VERSION ""

NS_ :

BS_:

BU_: XXX

BO_ 85 CID_GBIMZC: 8 XXX
 SG_ sig_pclxby : 40|1@1+ (1,0) [0|1] "" XXX
 SG_ sig_extefw : 56|8@1+ (1,0) [0|255] "" XXX

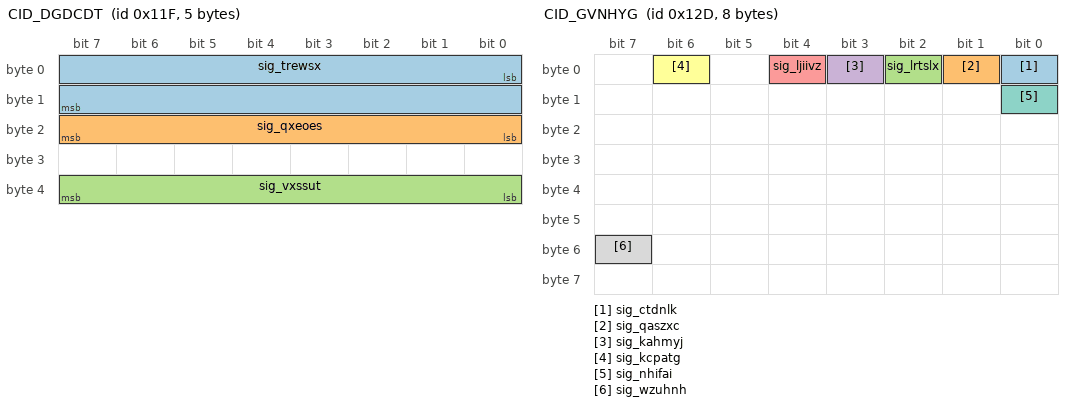
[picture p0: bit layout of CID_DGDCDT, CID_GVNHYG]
BO_ 287 CID_DGDCDT: 5 XXX
 SG_ sig_trewsx : 0|16@1- (0.1,0) [-450|450] "" XXX
 SG_ sig_qxeoes : 16|8@1+ (4,0) [0|1020] "" XXX
 SG_ sig_vxssut : 32|8@1+ (1,0) [0|255] "" XXX

BO_ 289 CID_SAXJDJ: 8 XXX
 SG_ sig_kdftpg : 0|12@1+ (1,0) [0|255] "" XXX

BO_ 301 CID_GVNHYG: 8 XXX
 SG_ sig_ctdnlk : 0|1@0+ (1,0) [0|1] "" XXX
 SG_ sig_qaszxc : 1|1@0+ (1,0) [0|1] "" XXX
 SG_ sig_lrtslx : 2|1@0+ (1,0) [0|1] "" XXX
 SG_ sig_kahmyj : 3|1@0+ (1,0) [0|1] "" XXX
 SG_ sig_ljiivz : 4|1@0+ (1,0) [0|1] "" XXX
 SG_ sig_kcpatg : 6|1@0+ (1,0) [0|1] "" XXX
 SG_ sig_nhifai : 8|1@0+ (1,0) [0|1] "" XXX
 SG_ sig_wzuhnh : 55|1@0+ (1,0) [0|1] "" XXX

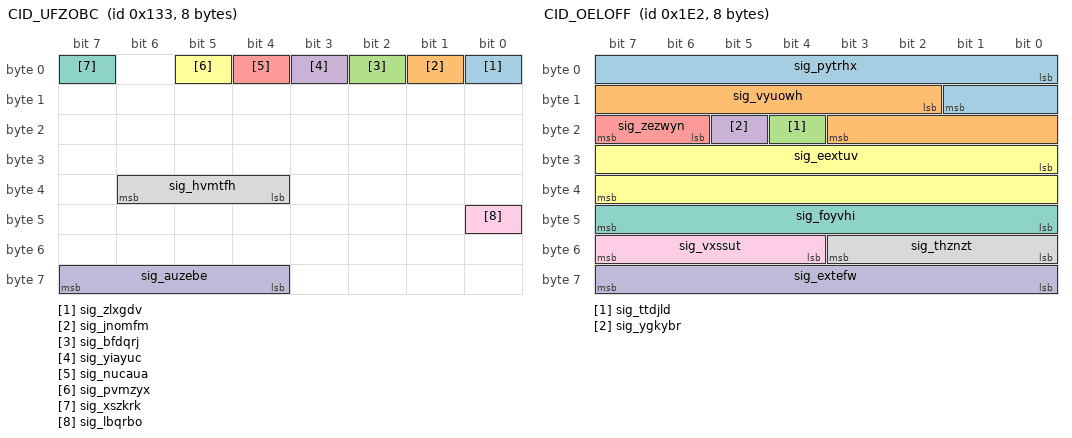
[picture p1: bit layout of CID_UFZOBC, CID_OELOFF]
BO_ 307 CID_UFZOBC: 8 XXX
 SG_ sig_zlxgdv : 0|1@0+ (1,0) [0|1] "" XXX
 SG_ sig_jnomfm : 1|1@1+ (1,0) [0|1] "" XXX
 SG_ sig_bfdqrj : 2|1@1+ (1,0) [0|1] "" XXX
 SG_ sig_yiayuc : 3|1@1+ (1,0) [0|1] "" XXX
 SG_ sig_nucaua : 4|1@0+ (1,0) [0|1] "" XXX
 SG_ sig_pvmzyx : 5|1@0+ (1,0) [0|1] "" XXX
 SG_ sig_xszkrk : 7|1@0+ (1,0) [0|1] "" XXX
 SG_ sig_hvmtfh : 36|3@1+ (1,0) [0|7] "" XXX
 SG_ sig_lbqrbo : 40|1@0+ (1,0) [0|1] "" XXX
 SG_ sig_auzebe : 63|4@0+ (1,0) [0|15] "" XXX

BO_ 482 CID_OELOFF: 8 XXX
 SG_ sig_pytrhx : 0|10@1- (0.01,0) [0|5] "" XXX
 SG_ sig_vyuowh : 10|10@1- (0.01,0) [-5|0] "" XXX
 SG_ sig_ttdjld : 20|1@0+ (1,0) [0|1] "" XXX
 SG_ sig_ygkybr : 21|1@0+ (1,0) [0|1] "" XXX
 SG_ sig_zezwyn : 22|2@1+ (1,0) [0|1] "" XXX
 SG_ sig_eextuv : 24|16@1- (0.1,0) [-780|779.9] "" XXX
 SG_ sig_foyvhi : 47|8@0+ (1,0) [0|255] "" XXX
 SG_ sig_thznzt : 48|4@1+ (1,0) [0|15] "" XXX
 SG_ sig_vxssut : 52|4@1+ (1,0) [0|15] "" XXX
 SG_ sig_extefw : 56|8@1+ (1,0) [0|255] "" XXX

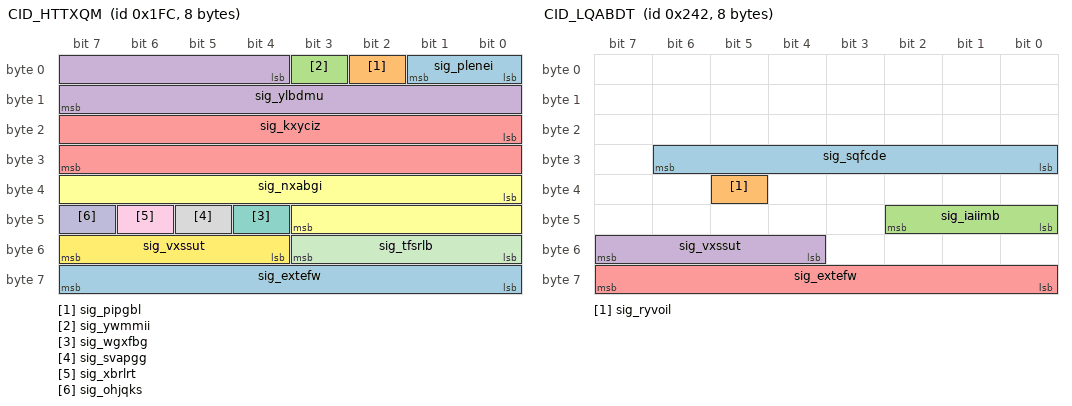
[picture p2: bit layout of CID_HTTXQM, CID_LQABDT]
BO_ 508 CID_HTTXQM: 8 XXX
 SG_ sig_plenei : 0|2@1+ (1,0) [0|1] "" XXX
 SG_ sig_pipgbl : 2|1@1+ (1,0) [0|1] "" XXX
 SG_ sig_ywmmii : 3|1@0+ (1,0) [0|1] "" XXX
 SG_ sig_ylbdmu : 4|12@1- (1,0) [-2048|2047] "" XXX
 SG_ sig_kxyciz : 16|16@1- (0.1,0) [-780|779.9] "Deg" XXX
 SG_ sig_nxabgi : 32|12@1- (1,0) [0|63] "" XXX
 SG_ sig_wgxfbg : 44|1@0+ (1,0) [0|1] "" XXX
 SG_ sig_svapgg : 45|1@1+ (1,0) [0|255] "" XXX
 SG_ sig_xbrlrt : 46|1@1+ (1,0) [0|1] "" XXX
 SG_ sig_ohjqks : 47|1@0+ (1,0) [0|3] "" XXX
 SG_ sig_tfsrlb : 48|4@1+ (1,0) [0|15] "" XXX
 SG_ sig_vxssut : 52|4@1+ (1,0) [0|15] "" XXX
 SG_ sig_extefw : 56|8@1+ (1,0) [0|255] "" XXX

BO_ 578 CID_LQABDT: 8 XXX
 SG_ sig_sqfcde : 30|7@0+ (1,0) [0|127] "" XXX
 SG_ sig_ryvoil : 37|1@0+ (1,0) [0|1] "" XXX
 SG_ sig_iaiimb : 40|3@1+ (1,0) [0|7] "" XXX
 SG_ sig_vxssut : 55|4@0+ (1,0) [0|15] "" XXX
 SG_ sig_extefw : 56|8@1+ (1,0) [0|255] "" XXX

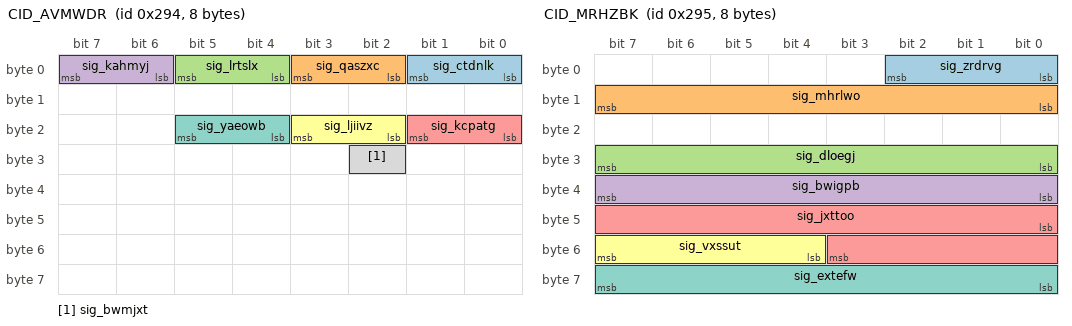
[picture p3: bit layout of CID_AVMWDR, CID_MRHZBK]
BO_ 660 CID_AVMWDR: 8 XXX
 SG_ sig_ctdnlk : 1|2@0+ (1,0) [0|3] "" XXX
 SG_ sig_qaszxc : 3|2@0+ (1,0) [0|3] "" XXX
 SG_ sig_lrtslx : 5|2@0+ (1,0) [0|3] "" XXX
 SG_ sig_kahmyj : 7|2@0+ (1,0) [0|3] "" XXX
 SG_ sig_kcpatg : 17|2@0+ (1,0) [0|3] "" XXX
 SG_ sig_ljiivz : 19|2@0+ (1,0) [0|3] "" XXX
 SG_ sig_yaeowb : 21|2@0+ (1,0) [0|3] "" XXX
 SG_ sig_bwmjxt : 26|1@0+ (1,0) [0|1] "" XXX

BO_ 661 CID_MRHZBK: 8 XXX
 SG_ sig_zrdrvg : 2|3@0+ (1,0) [0|7] "" XXX
 SG_ sig_mhrlwo : 15|8@0+ (1,0) [0|255] "" XXX
 SG_ sig_dloegj : 31|8@0+ (1,0) [0|255] "" XXX
 SG_ sig_bwigpb : 32|8@1+ (1,0) [0|255] "" XXX
 SG_ sig_jxttoo : 40|12@1+ (1,0) [0|255] "" XXX
 SG_ sig_vxssut : 52|4@1+ (1,0) [0|15] "" XXX
 SG_ sig_extefw : 63|8@0+ (1,0) [0|255] "" XXX

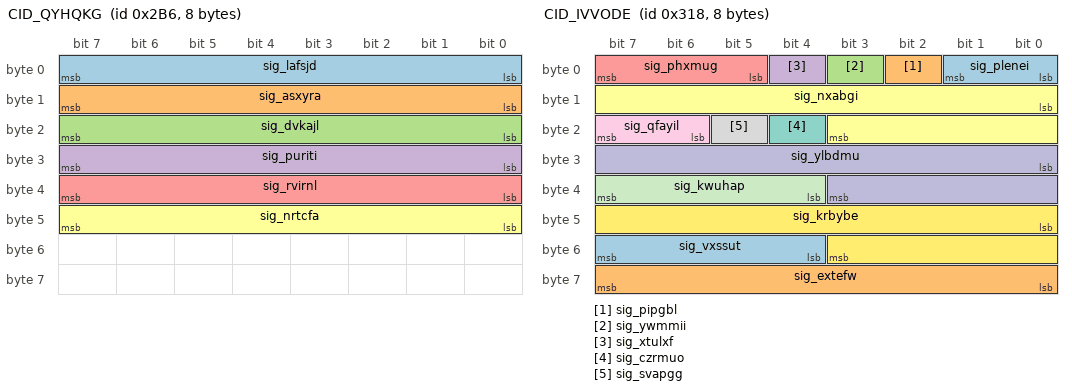
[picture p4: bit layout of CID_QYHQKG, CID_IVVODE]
BO_ 694 CID_QYHQKG: 8 XXX
 SG_ sig_lafsjd : 7|8@0+ (1,0) [0|255] "" XXX
 SG_ sig_asxyra : 15|8@0+ (1,0) [0|255] "" XXX
 SG_ sig_dvkajl : 23|8@0+ (1,0) [0|255] "" XXX
 SG_ sig_puriti : 31|8@0+ (1,0) [0|255] "" XXX
 SG_ sig_rvirnl : 39|8@0+ (1,0) [0|255] "" XXX
 SG_ sig_nrtcfa : 47|8@0+ (1,0) [0|255] "" XXX

BO_ 790 CID_UAIBRB: 8 XXX
 SG_ sig_huncqz : 3|4@0+ (1,0) [0|1] "" XXX
 SG_ sig_enhzmd : 4|2@1+ (1,0) [0|3] "" XXX
 SG_ sig_akbsrh : 6|2@1+ (1,0) [0|3] "" XXX
 SG_ sig_simhtp : 8|2@1+ (1,0) [0|3] "" XXX
 SG_ sig_eokokl : 10|1@1+ (1,0) [0|1] "" XXX
 SG_ sig_jzsvsn : 11|4@1+ (1,0) [0|1] "" XXX
 SG_ sig_sukzsg : 15|1@0+ (1,0) [0|1] "" XXX
 SG_ sig_eextuv : 16|11@1- (1,0) [-1024|1023] "" XXX
 SG_ sig_ttdjld : 27|1@1+ (1,0) [0|1] "" XXX
 SG_ sig_ygkybr : 28|1@1+ (1,0) [0|3] "" XXX
 SG_ sig_osdfpt : 29|1@0+ (1,0) [0|1] "" XXX
 SG_ sig_uwnvwp : 30|1@0+ (1,0) [0|1] "" XXX
 SG_ sig_jrvsuu : 31|1@0+ (1,0) [0|1] "" XXX
 SG_ sig_rhxdpg : 32|2@1+ (1,0) [0|3] "" XXX
 SG_ sig_vrpyop : 34|2@1+ (1,0) [0|3] "" XXX
 SG_ sig_swhtkj : 36|4@1+ (1,0) [0|3] "" XXX
 SG_ sig_rrveqr : 40|8@1+ (5,-5) [-5|1270] "" XXX
 SG_ sig_ybpoqw : 49|2@0+ (1,0) [0|3] "" XXX
 SG_ sig_ozvhkc : 51|2@0+ (1,0) [0|3] "" XXX
 SG_ sig_vxssut : 52|4@1+ (1,0) [0|15] "" XXX
 SG_ sig_extefw : 56|8@1+ (1,0) [0|15] "" XXX

BO_ 792 CID_IVVODE: 8 XXX
 SG_ sig_plenei : 0|2@1+ (1,0) [0|1] "" XXX
 SG_ sig_pipgbl : 2|1@1+ (1,0) [0|1] "" XXX
 SG_ sig_ywmmii : 3|1@1+ (1,0) [0|1] "" XXX
 SG_ sig_xtulxf : 4|1@1+ (1,0) [0|1] "" XXX
 SG_ sig_phxmug : 5|3@1+ (1,0) [0|1] "" XXX
 SG_ sig_nxabgi : 8|12@1- (1,0) [-2048|2047] "" XXX
 SG_ sig_czrmuo : 20|1@1+ (1,0) [0|1] "" XXX
 SG_ sig_svapgg : 21|1@1+ (1,0) [0|1] "" XXX
 SG_ sig_qfayil : 22|2@1+ (1,0) [0|15] "" XXX
 SG_ sig_ylbdmu : 24|12@1- (1,0) [-2048|2047] "" XXX
 SG_ sig_kwuhap : 36|4@1+ (1,0) [0|15] "" XXX
 SG_ sig_krbybe : 40|12@1+ (1,0) [0|4095] "" XXX
 SG_ sig_vxssut : 52|4@1+ (1,0) [0|15] "" XXX
 SG_ sig_extefw : 56|8@1+ (1,0) [0|255] "" XXX

BO_ 813 CID_ZJZCZS: 8 XXX
 SG_ sig_kobqec : 0|9@1+ (0.5,0) [0|255.5] "" XXX
 SG_ sig_xymflo : 9|1@1+ (1,0) [0|1] "" XXX
 SG_ sig_mjxeax : 10|3@1+ (1,0) [0|7] "" XXX
 SG_ sig_blhgda : 13|3@1+ (1,0) [0|7] "" XXX
 SG_ sig_asaftx : 16|1@1+ (1,0) [0|1] "" XXX
 SG_ sig_idbcnx : 17|1@1+ (1,0) [0|1] "" XXX
 SG_ sig_ywmmii : 18|1@1+ (1,0) [0|1] "" XXX
 SG_ sig_ntwqev : 19|3@1+ (1,0) [0|1] "" XXX
 SG_ sig_lnxkch : 22|1@0+ (1,0) [0|1] "" XXX
 SG_ sig_bdagis : 23|1@0+ (1,0) [0|1] "" XXX
 SG_ sig_simhtp : 24|1@1+ (1,0) [0|1] "" XXX
 SG_ sig_wqhsoe : 25|7@1+ (1,0) [0|127] "" XXX
 SG_ sig_gjrjdi : 32|4@1+ (1,0) [0|15] "" XXX
 SG_ sig_svvfpf : 36|12@1+ (1,0) [0|4095] "" XXX
 SG_ sig_vxssut : 48|4@1+ (1,0) [0|15] "" XXX
 SG_ sig_fuuhtu : 55|4@0+ (1,0) [0|15] "" XXX
 SG_ sig_extefw : 56|8@1+ (1,0) [0|255] "" XXX

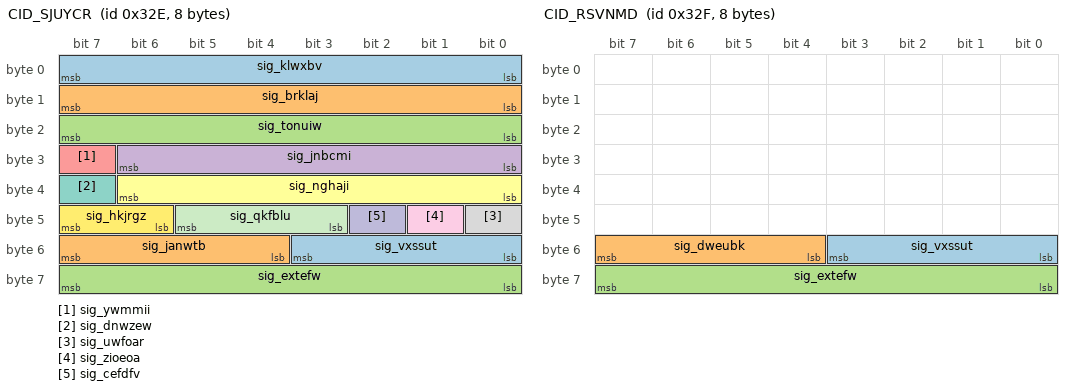
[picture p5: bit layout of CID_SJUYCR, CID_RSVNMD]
BO_ 814 CID_SJUYCR: 8 XXX
 SG_ sig_klwxbv : 0|8@1+ (0.05,-5) [-100|155] "" XXX
 SG_ sig_brklaj : 8|8@1+ (0.05,-5) [0|1.26] "" XXX
 SG_ sig_tonuiw : 16|8@1+ (0.05,-5) [0|1.26] "" XXX
 SG_ sig_jnbcmi : 24|7@1+ (0.2,0) [0|12.7] "" XXX
 SG_ sig_ywmmii : 31|1@0+ (1,0) [0|1] "" XXX
 SG_ sig_nghaji : 32|7@1+ (0.2,-16) [0|12.7] "" XXX
 SG_ sig_dnwzew : 39|1@0+ (1,0) [0|1] "" XXX
 SG_ sig_uwfoar : 40|1@0+ (1,0) [0|1] "" XXX
 SG_ sig_zioeoa : 41|1@0+ (1,0) [0|1] "" XXX
 SG_ sig_cefdfv : 42|1@1+ (1,0) [0|3] "" XXX
 SG_ sig_qkfblu : 45|3@0+ (1,0) [0|1] "" XXX
 SG_ sig_hkjrgz : 46|2@1+ (1,0) [0|3] "" XXX
 SG_ sig_vxssut : 48|4@1+ (1,0) [0|15] "" XXX
 SG_ sig_janwtb : 55|4@0+ (1,0) [0|15] "" XXX
 SG_ sig_extefw : 56|8@1+ (1,0) [0|255] "" XXX

BO_ 815 CID_RSVNMD: 8 XXX
 SG_ sig_vxssut : 48|4@1+ (1,0) [0|15] "" XXX
 SG_ sig_dweubk : 55|4@0+ (1,0) [0|15] "" XXX
 SG_ sig_extefw : 56|8@1+ (1,0) [0|255] "" XXX

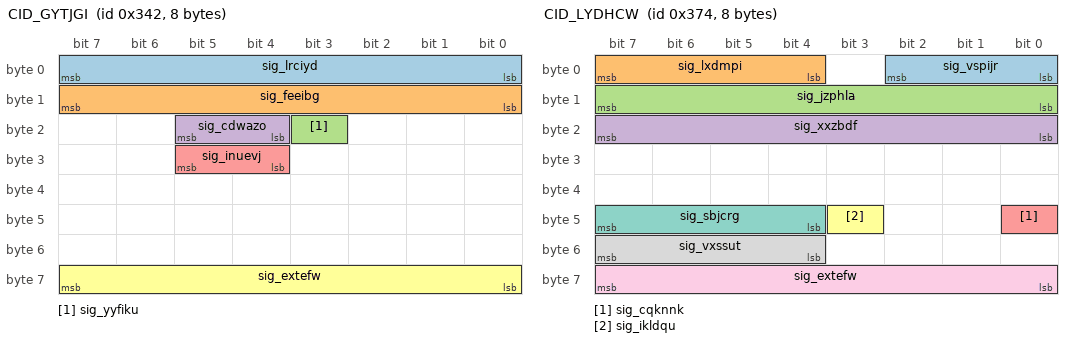
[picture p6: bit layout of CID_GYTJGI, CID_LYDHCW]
BO_ 834 CID_GYTJGI: 8 XXX
 SG_ sig_lrciyd : 0|8@1+ (0.01,0) [0|2.55] "" XXX
 SG_ sig_feeibg : 8|8@1+ (0.01,0) [0|2.55] "" XXX
 SG_ sig_yyfiku : 19|1@1+ (1,0) [0|1] "" XXX
 SG_ sig_cdwazo : 20|2@1+ (1,0) [0|255] "" XXX
 SG_ sig_inuevj : 28|2@1+ (1,0) [0|1] "" XXX
 SG_ sig_extefw : 56|8@1+ (1,0) [0|255] "" XXX

BO_ 884 CID_LYDHCW: 8 MRR
 SG_ sig_vspijr : 2|3@0+ (1,0) [0|3] "" MRR
 SG_ sig_lxdmpi : 7|4@0+ (1,0) [0|15] "" MRR
 SG_ sig_jzphla : 15|8@0+ (0.1,-12) [0|255] "" MRR
 SG_ sig_xxzbdf : 23|8@0+ (1,-100) [0|255] "" MRR
 SG_ sig_cqknnk : 40|1@0+ (1,0) [0|3] "" MRR
 SG_ sig_ikldqu : 43|1@0+ (1,0) [0|1] "" XXX
 SG_ sig_sbjcrg : 44|4@1+ (1,0) [0|15] "" XXX
 SG_ sig_vxssut : 52|4@1+ (1,0) [0|15] "" MRR
 SG_ sig_extefw : 56|8@1+ (1,0) [0|255] "" MRR

BO_ 944 CID_YSPDYY: 8 XXX
 SG_ sig_vhlmon : 1|2@0+ (1,0) [0|3] "" XXX
 SG_ sig_xbfmji : 2|1@0+ (1,0) [0|1] "" XXX
 SG_ sig_kmuhlm : 4|2@0+ (1,0) [0|3] "" XXX
 SG_ sig_lxddok : 5|1@0+ (1,0) [0|1] "" XXX
 SG_ sig_kzxnbb : 6|1@0+ (1,0) [0|1] "" XXX
 SG_ sig_vgefja : 7|1@0+ (1,0) [0|1] "" XXX
 SG_ sig_zftmev : 8|1@0+ (1,0) [0|1] "" XXX
 SG_ sig_ijqmaq : 11|3@0+ (1,0) [0|7] "" XXX
 SG_ sig_lhksdo : 12|1@0+ (1,0) [0|1] "" XXX
 SG_ sig_cusoej : 14|2@0+ (1,0) [0|3] "" XXX
 SG_ sig_hnzyqe : 15|1@0+ (1,0) [0|1] "" XXX
 SG_ sig_dowjgz : 16|1@0+ (1,0) [0|1] "" XXX
 SG_ sig_pkpvfy : 18|2@0+ (1,0) [0|3] "" XXX
 SG_ sig_qtoszd : 19|1@0+ (1,0) [0|1] "" XXX
 SG_ sig_gfqwoo : 23|4@0+ (1,0) [0|15] "" XXX
 SG_ sig_hrchlh : 24|28@1+ (1,0) [0|268435455] "" XXX
 SG_ sig_vxssut : 52|4@1+ (1,0) [0|15] "" XXX
 SG_ sig_extefw : 56|8@1+ (1,0) [0|255] "" XXX

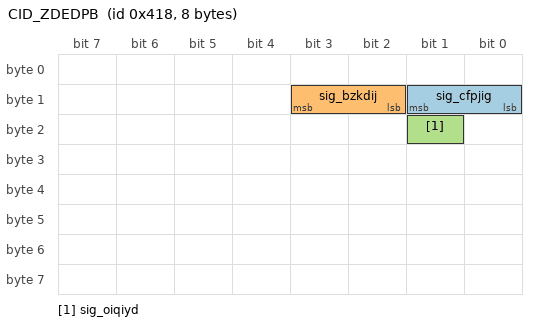
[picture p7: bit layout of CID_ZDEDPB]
BO_ 1048 CID_ZDEDPB: 8 XXX
 SG_ sig_cfpjig : 9|2@0+ (1,0) [0|1] "" XXX
 SG_ sig_bzkdij : 11|2@0+ (1,0) [0|1] "" XXX
 SG_ sig_oiqiyd : 17|1@0+ (1,0) [0|1] "" XXX

VAL_ 578 sig_iaiimb 4 "D" 2 "R" 3 "N" 1 "P";
VAL_ 790 sig_huncqz 11 "AutoFullBeamActive" 2 "AutoFullBeamInactive";
VAL_ 790 sig_enhzmd 0 "GRAY" 1 "GREEN" 2 "YELLOW" 3 "RED";
VAL_ 790 sig_akbsrh 3 "ALARM_AND_LKA" 2 "LKA" 1 "ALARM" 0 "DISABLE";
VAL_ 790 sig_vrpyop 0 "GRAY" 1 "GREEN" 2 "YELLOW" 3 "RED";
VAL_ 790 sig_ybpoqw 0 "VIBRATION" 1 "AUDIO" 2 "AUDIO_AND_VIBRATION";
VAL_ 792 sig_plenei 0 "NotReady" 1 "Ready" 2 "Active" 3 "TemporaryFail";
VAL_ 813 sig_mjxeax 4 "4BAR" 3 "3BAR" 2 "2BAR" 1 "1BAR";
VAL_ 813 sig_ntwqev 0 "OFF" 2 "ACC_ON" 3 "ACC_ACTIVE" 5 "FORCE_ACCEL" 7 "ERROR";
VAL_ 813 sig_wqhsoe 36 "ACC_ERROR" 22 "OVERRIDE" 12 "ENGAGE" 8 "DISENGAGE" 20 "ACC_ON" 32 "ACC_OFF" 48 "CHECK_GEAR_D" 16 "FORCE_ACCEL" 0 "NONE";
VAL_ 814 sig_qkfblu 0 "Off" 1 "Passive" 2 "StandBy" 3 "ActiveControl" 4 "BrakeOnly" 5 "Override" 6 "Standstill" 7 "Failure";
VAL_ 814 sig_hkjrgz 0 "Softoff" 1 "Fastoff" 2 "Immediateoff" 3 "Initial";
VAL_ 834 sig_cdwazo 2 "SPORT" 1 "ECO" 0 "SNOW";
VAL_ 834 sig_inuevj 3 "HEV" 2 "FORCE_EV" 1 "EV";
VAL_ 944 sig_kmuhlm 0 "NOTPRESSED" 1 "DOWN_SETSPEED" 3 "UP_RESETSPEED";
